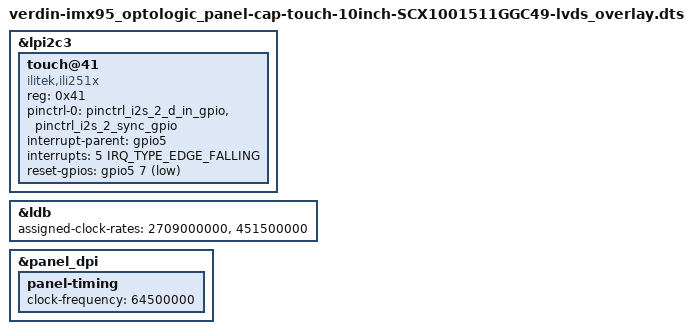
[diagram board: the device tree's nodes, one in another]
// SPDX-License-Identifier: GPL-2.0-or-later OR MIT
/*
 * Copyright © 2025 OPTO logic Tenchnology S.A.
 * Author: Elinor Montmasson <elinor.montmasson@savoirfairelinux.com>
 */

// Verdin iMX95 single-channel LVDS for 10.1 inch OPTO Logic display (SCX1001511GGC49)
// Extends verdin-imx95_panel-cap-touch-10inch-lvds_overlay.dts

/dts-v1/;
/plugin/;

#include <dt-bindings/gpio/gpio.h>
#include <dt-bindings/interrupt-controller/irq.h>

#include "verdin-imx95_optologic_lvds.dtsi"
#include "display-scx10.dtsi"

/* Verdin I2C_2_DSI */
&lpi2c3 {
	touch@41 {
		compatible = "ilitek,ili251x";
		reg = <0x41>;
		pinctrl-names = "default";
		pinctrl-0 = <&pinctrl_i2s_2_d_in_gpio>, <&pinctrl_i2s_2_sync_gpio>;
		/* Verdin I2S_2_SYNC as GPIO (SODIMM 44) */
		interrupt-parent = <&gpio5>;
		interrupts = <5 IRQ_TYPE_EDGE_FALLING>;
		/* Verdin I2S_2_D_IN as GPIO (SODIMM 48) */
		reset-gpios = <&gpio5 7 GPIO_ACTIVE_LOW>;
		status = "okay";
	};
};

&ldb {
	/* 6*7*pixelclk and 7*pixelclk, pixelclock: 64.5 MHz */
	assigned-clock-rates = <2709000000>, <451500000>;
};

&panel_dpi {
	panel-timing {
		/* Set back typical frequency which is compatible with imx95 drivers */
		clock-frequency = <64500000>;
	};
};
